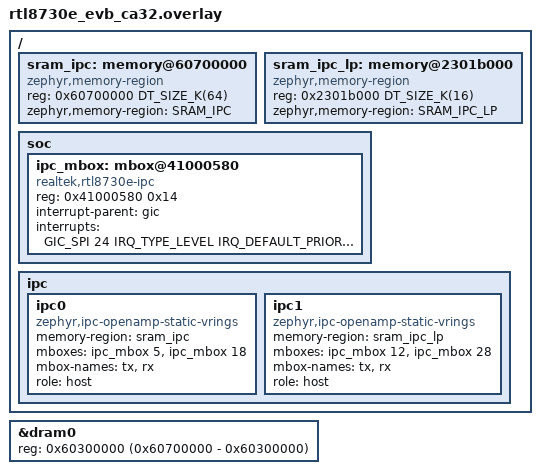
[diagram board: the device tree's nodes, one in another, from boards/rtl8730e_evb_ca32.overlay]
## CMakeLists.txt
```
# Copyright (c) 2026 Realtek Semiconductor Corp.
# SPDX-License-Identifier: Apache-2.0

cmake_minimum_required(VERSION 3.20.0)

find_package(Zephyr REQUIRED HINTS $ENV{ZEPHYR_BASE})
project(rtl8730e_rpmsg)

target_sources(app PRIVATE src/main.c)
```

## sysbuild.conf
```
# The vendor IMG1 stays the bootloader. With no sysbuild bootloader the CA32
# build runs handle_amebasmart, folding the KM4/KM0 image2 into app.bin.
SB_CONFIG_BOOTLOADER_NONE=y

# Build the KM4 and KM0 remotes from this sample. Sysbuild orders them before the
# CA32 image so their image2 exists at combine time.
SB_CONFIG_RTL8730E_BUILD_KM4_APP=y
SB_CONFIG_RTL8730E_KM4_APP_SOURCE_DIR="."
SB_CONFIG_RTL8730E_BUILD_KM0_APP=y
SB_CONFIG_RTL8730E_KM0_APP_SOURCE_DIR="."
```

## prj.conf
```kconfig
CONFIG_PRINTK=y
CONFIG_LOG=y
CONFIG_IPC_SERVICE_LOG_LEVEL_INF=y

CONFIG_HEAP_MEM_POOL_SIZE=4096

CONFIG_IPC_SERVICE=y
CONFIG_MBOX=y
CONFIG_OPENAMP=y

# Shared memory survives warm reset, so each core zeroes its vdev status at init.
# Otherwise a remote reads stale DRIVER_OK and its NS announcement is lost when
# the host reinitializes the vrings; the remotes boot long before the CA32 host,
# so the remote reset is safe. Each option only affects instances of its role.
CONFIG_IPC_SERVICE_BACKEND_RPMSG_SHMEM_RESET=y
CONFIG_IPC_SERVICE_BACKEND_RPMSG_SHMEM_RESET_REMOTE=y

# CONFIG_OPENAMP_WITH_DCACHE stays off: no core caches the vrings. CA32 maps
# them via REGION_KM*_VRING, KM4 via zephyr,memory-attr, and KM0 has no D-cache.
```

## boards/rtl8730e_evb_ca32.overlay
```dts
/*
 * Copyright (c) 2026 Realtek Semiconductor Corp.
 *
 * SPDX-License-Identifier: Apache-2.0
 *
 * CA32 is the rpmsg host for both remotes. Both instances share IPCAP and its
 * GIC SPI 24, each on disjoint bits.
 *
 * mbox cells are absolute register bits (see realtek,rtl8730e-ipc.yaml):
 *   KM4 link: tx = bit 5  (AP_TO_NP ch5), rx = bit 18 (NP_TO_AP ch2)
 *   KM0 link: tx = bit 12 (AP_TO_LP ch4), rx = bit 28 (LP_TO_AP ch4)
 *
 * The Cortex-A arm_mmu ignores zephyr,memory-attr, so REGION_KM4_VRING and
 * REGION_KM0_VRING in mmu_regions.c map the shared regions non-cacheable.
 */

#include <zephyr/dt-bindings/interrupt-controller/arm-gic.h>

/ {
	/*
	 * KM4 vrings and buffers at the base of KM4_DRAM_HEAP_EXT. Non-secure
	 * PSRAM at the same address on CA32 and KM4.
	 */
	sram_ipc: memory@60700000 {
		compatible = "zephyr,memory-region", "mmio-sram";
		reg = <0x60700000 DT_SIZE_K(64)>;
		zephyr,memory-region = "SRAM_IPC";
	};

	/*
	 * KM0 cannot reach PSRAM, so its vrings live in KM0 SRAM, which CA32 also
	 * reaches. CA32 maps it non-cacheable through REGION_KM0_VRING.
	 */
	sram_ipc_lp: memory@2301b000 {
		compatible = "zephyr,memory-region", "mmio-sram";
		reg = <0x2301b000 DT_SIZE_K(16)>;
		zephyr,memory-region = "SRAM_IPC_LP";
	};

	soc {
		ipc_mbox: mbox@41000580 {
			compatible = "realtek,rtl8730e-ipc";
			reg = <0x41000580 0x14>;
			interrupt-parent = <&gic>;
			interrupts = <GIC_SPI 24 IRQ_TYPE_LEVEL IRQ_DEFAULT_PRIORITY>;
			#mbox-cells = <1>;
			status = "okay";
		};
	};

	ipc {
		ipc0: ipc0 {
			compatible = "zephyr,ipc-openamp-static-vrings";
			memory-region = <&sram_ipc>;
			mboxes = <&ipc_mbox 5>, <&ipc_mbox 18>;
			mbox-names = "tx", "rx";
			role = "host";
			status = "okay";
		};

		ipc1: ipc1 {
			compatible = "zephyr,ipc-openamp-static-vrings";
			memory-region = <&sram_ipc_lp>;
			mboxes = <&ipc_mbox 12>, <&ipc_mbox 28>;
			mbox-names = "tx", "rx";
			role = "host";
			status = "okay";
		};
	};
};

/*
 * Shrink dram0 to CA32_BL3_DRAM_NS so .bss and heap stay off the KM4 vrings.
 * AMEBASMART_DRAM_END follows, so REGION_KM4_VRING stays out of REGION_DRAM_BEYOND.
 */
&dram0 {
	reg = <0x60300000 (0x60700000 - 0x60300000)>;
};
```

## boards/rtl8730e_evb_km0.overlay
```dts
/*
 * Copyright (c) 2026 Realtek Semiconductor Corp.
 *
 * SPDX-License-Identifier: Apache-2.0
 *
 * KM0 (Cortex-M23, LP core) is an rpmsg remote on IPCLP, NVIC IRQ 0.
 *
 * mbox cells are absolute register bits (see realtek,rtl8730e-ipc.yaml):
 *   tx = bit 4  (LP_TO_AP ch4)
 *   rx = bit 20 (AP_TO_LP ch4, RX-full group starts at bit 16)
 *
 * KM0 cannot reach PSRAM, so the vrings live in KM0 SRAM, the only window shared
 * with CA32. KM0 has no D-cache; ATTR_MPU_RAM_NOCACHE only gives an explicit MPU map.
 */

#include <zephyr/dt-bindings/memory-attr/memory-attr-arm.h>

/ {
	sram_ipc_lp: memory@2301b000 {
		compatible = "zephyr,memory-region", "mmio-sram";
		reg = <0x2301b000 DT_SIZE_K(16)>;
		zephyr,memory-region = "SRAM_IPC_LP";
		zephyr,memory-attr = <DT_MEM_ARM(ATTR_MPU_RAM_NOCACHE)>;
	};

	soc {
		ipc_mbox: mbox@42008600 {
			compatible = "realtek,rtl8730e-ipc";
			reg = <0x42008600 0x14>;
			interrupt-parent = <&nvic>;
			interrupts = <0 3>;
			#mbox-cells = <1>;
			status = "okay";
		};
	};

	ipc {
		ipc0: ipc0 {
			compatible = "zephyr,ipc-openamp-static-vrings";
			memory-region = <&sram_ipc_lp>;
			mboxes = <&ipc_mbox 4>, <&ipc_mbox 20>;
			mbox-names = "tx", "rx";
			role = "remote";
			status = "okay";
		};
	};
};

/* Reserve the top 16 KB of KM0_BD_RAM for the shared vring window. */
&sram0 {
	reg = <0x23002020 (0x2301b000 - 0x23002020)>;
};
```

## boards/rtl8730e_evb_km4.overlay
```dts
/*
 * Copyright (c) 2026 Realtek Semiconductor Corp.
 *
 * SPDX-License-Identifier: Apache-2.0
 *
 * KM4 (Cortex-M55) is an rpmsg remote on IPCNP, NVIC IRQ 24.
 *
 * mbox cells are absolute register bits (see realtek,rtl8730e-ipc.yaml):
 *   tx = bit 2  (NP_TO_AP ch2)
 *   rx = bit 21 (AP_TO_NP ch5, RX-full group starts at bit 16)
 *
 * The vrings sit above KM4 sram0 (0x60000020..0x6015B000), so sram0 needs no
 * shrink. KM4 has a D-cache, so ATTR_MPU_RAM_NOCACHE maps the region non-cacheable.
 */

#include <zephyr/dt-bindings/memory-attr/memory-attr-arm.h>

/ {
	sram_ipc: memory@60700000 {
		compatible = "zephyr,memory-region", "mmio-sram";
		reg = <0x60700000 DT_SIZE_K(64)>;
		zephyr,memory-region = "SRAM_IPC";
		zephyr,memory-attr = <DT_MEM_ARM(ATTR_MPU_RAM_NOCACHE)>;
	};

	soc {
		ipc_mbox: mbox@41000500 {
			compatible = "realtek,rtl8730e-ipc";
			reg = <0x41000500 0x14>;
			interrupt-parent = <&nvic>;
			interrupts = <24 3>;
			#mbox-cells = <1>;
			status = "okay";
		};
	};

	ipc {
		ipc0: ipc0 {
			compatible = "zephyr,ipc-openamp-static-vrings";
			memory-region = <&sram_ipc>;
			mboxes = <&ipc_mbox 2>, <&ipc_mbox 21>;
			mbox-names = "tx", "rx";
			role = "remote";
			status = "okay";
		};
	};
};
```

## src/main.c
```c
/*
 * Copyright (c) 2026 Realtek Semiconductor Corp.
 *
 * SPDX-License-Identifier: Apache-2.0
 *
 * ipc_service static-vrings link test. The CA32 host runs two instances:
 *   - ipc0: CA32 <-> KM4 (PSRAM @ 0x60700000)
 *   - ipc1: CA32 <-> KM0 (KM0 SRAM @ 0x2301B000)
 *
 * Devicetree sets each core's role and instances; remotes define only ipc0.
 * Each bound endpoint sends a running counter and logs what it receives.
 */

#include <zephyr/kernel.h>
#include <zephyr/device.h>
#include <zephyr/ipc/ipc_service.h>
#include <string.h>

#include <zephyr/logging/log.h>
LOG_MODULE_REGISTER(rtl8730e_rpmsg, LOG_LEVEL_INF);

struct link {
	const struct device *dev;
	const char *label;
	struct ipc_ept ep;
	struct ipc_ept_cfg cfg;
	struct k_sem bound_sem;
	uint32_t counter;
};

static void ep_bound(void *priv)
{
	struct link *l = priv;

	k_sem_give(&l->bound_sem);
	LOG_INF("[%s] endpoint bound", l->label);
}

static void ep_recv(const void *data, size_t len, void *priv)
{
	struct link *l = priv;
	uint32_t val = 0;

	memcpy(&val, data, MIN(len, sizeof(val)));
	LOG_INF("[%s] received %zu bytes: %u", l->label, len, val);
}

static void ep_error(const char *message, void *priv)
{
	struct link *l = priv;

	LOG_ERR("[%s] rpmsg error: %s", l->label, message);
}

#define LINK_INITIALIZER(node_id, _label)                                      \
	{                                                                      \
		.dev = DEVICE_DT_GET(node_id),                                 \
		.label = _label,                                               \
	}

static struct link links[] = {
	LINK_INITIALIZER(DT_NODELABEL(ipc0), "ipc0"),
#if DT_NODE_EXISTS(DT_NODELABEL(ipc1))
	LINK_INITIALIZER(DT_NODELABEL(ipc1), "ipc1"),
#endif
};

#define NUM_LINKS ARRAY_SIZE(links)

static int link_setup(struct link *l)
{
	int ret;

	k_sem_init(&l->bound_sem, 0, 1);

	l->cfg.name = "rtl8730e_rpmsg";
	l->cfg.priv = l;
	l->cfg.cb.bound = ep_bound;
	l->cfg.cb.received = ep_recv;
	l->cfg.cb.error = ep_error;

	ret = ipc_service_open_instance(l->dev);
	if ((ret < 0) && (ret != -EALREADY)) {
		LOG_ERR("[%s] ipc_service_open_instance() failed: %d", l->label, ret);
		return ret;
	}

	ret = ipc_service_register_endpoint(l->dev, &l->ep, &l->cfg);
	if (ret < 0) {
		LOG_ERR("[%s] ipc_service_register_endpoint() failed: %d", l->label, ret);
		return ret;
	}

	return 0;
}

int main(void)
{
	LOG_INF("RTL8730E rpmsg sample started (%zu link(s))", NUM_LINKS);

	for (size_t i = 0; i < NUM_LINKS; i++) {
		int ret = link_setup(&links[i]);

		if (ret < 0) {
			return ret;
		}
	}

	/* Wait for every link to bind before starting traffic. */
	for (size_t i = 0; i < NUM_LINKS; i++) {
		k_sem_take(&links[i].bound_sem, K_FOREVER);
	}

	while (1) {
		for (size_t i = 0; i < NUM_LINKS; i++) {
			struct link *l = &links[i];
			int ret = ipc_service_send(&l->ep, &l->counter, sizeof(l->counter));

			if (ret < 0 && ret != -ENOMEM) {
				LOG_ERR("[%s] ipc_service_send() failed: %d", l->label, ret);
			} else if (ret >= 0) {
				LOG_INF("[%s] sent %u", l->label, l->counter);
				l->counter++;
			}
		}
		k_msleep(1000);
	}

	return 0;
}
```
